# STM32N645 register map
File version: 1.0
CPU: CM55 r0p1, little endian, no MPU, FPU, vendor SysTick, 8 interrupt priority bits
Registers are 32-bit, read-write, reset 0x0 unless marked. A register's access mark holds for its fields unless they carry their own. Offsets are from the block's base; [hi:lo] are bit positions; lines under a group give offsets from that group; {n}, {i} and the like mark numbered series.

## ADC1 — Analog-to-digital converters
Base 0x40022000
Same registers: ADC2 0x40022100, ADC1_S 0x50022000, ADC2_S 0x50022100
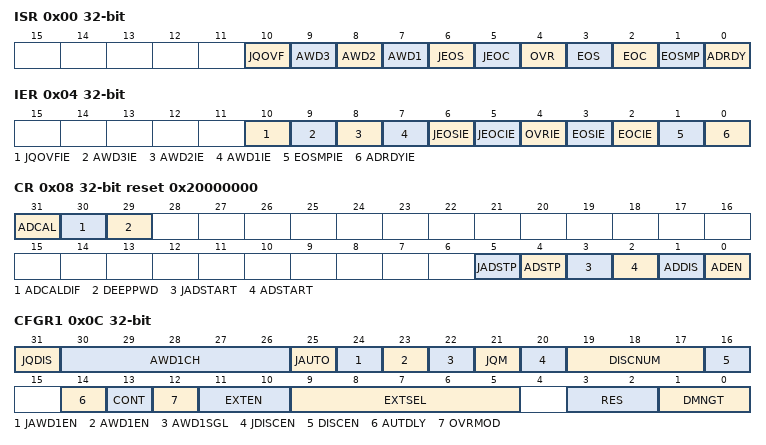
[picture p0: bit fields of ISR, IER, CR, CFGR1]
0x00 ISR — ADC interrupt and status register
  [10] JQOVF — Injected context queue overflow
  [9] AWD3 — Analog watchdog 3 flag
  [8] AWD2 — Analog watchdog 2 flag
  [7] AWD1 — Analog watchdog 1 flag
  [6] JEOS — Injected channel end of sequence flag
  [5] JEOC — Injected channel end of conversion flag
  [4] OVR — ADC overrun
  [3] EOS — End of regular sequence flag
  [2] EOC — End of conversion flag
  [1] EOSMP — End of sampling flag
  [0] ADRDY — ADC ready
0x04 IER — ADC interrupt enable register
  [10] JQOVFIE — Injected context queue overflow interrupt enable
  [9] AWD3IE — Analog watchdog 3 interrupt enable
  [8] AWD2IE — Analog watchdog 2 interrupt enable
  [7] AWD1IE — Analog watchdog 1 interrupt enable
  [6] JEOSIE — End of injected sequence of conversions interrupt enable
  [5] JEOCIE — End of injected conversion interrupt enable
  [4] OVRIE — Overrun interrupt enable
  [3] EOSIE — End of regular sequence of conversions interrupt enable
  [2] EOCIE — End of regular conversion interrupt enable
  [1] EOSMPIE — End of sampling flag interrupt enable for regular conversions
  [0] ADRDYIE — ADC ready interrupt enable
0x08 CR reset 0x20000000 — ADC control register
  [31] ADCAL — ADC calibration
  [30] ADCALDIF — Differential mode for calibration
  [29] DEEPPWD — Deep-power-down enable
  [5] JADSTP — ADC stop of injected conversion command
  [4] ADSTP — ADC stop of regular conversion command
  [3] JADSTART — ADC start of injected conversion
  [2] ADSTART — ADC start of regular conversion
  [1] ADDIS — ADC disable command
  [0] ADEN — ADC enable control
0x0C CFGR1 — ADC configuration register
  [31] JQDIS — Injected queue disable
  [30:26] AWD1CH — Analog watchdog 1 channel selection
  [25] JAUTO — Automatic injected group conversion
  [24] JAWD1EN — Analog watchdog 1 enable on injected channels
  [23] AWD1EN — Analog watchdog 1 enable on regular channels
  [22] AWD1SGL — Enable the watchdog 1 on a single channel or on all channels
  [21] JQM — JSQR queue mode
  [20] JDISCEN — Discontinuous mode on injected channels
  [19:17] DISCNUM — Discontinuous mode channel count
  [16] DISCEN — Discontinuous mode for regular channels
  [14] AUTDLY — Delayed conversion mode
  [13] CONT — Single / Continuous conversion mode for regular conversions
  [12] OVRMOD — Overrun mode
  [11:10] EXTEN — External trigger enable and polarity selection for regular channels
  [9:5] EXTSEL — External trigger selection for regular group
  [3:2] RES — Data resolution
  [1:0] DMNGT — Data management configuration
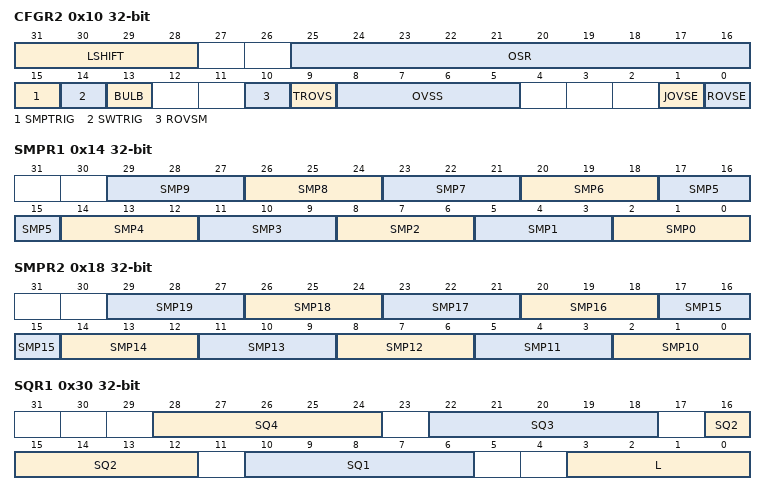
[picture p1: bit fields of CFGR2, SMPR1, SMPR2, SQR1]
0x10 CFGR2 — ADC configuration register 2
  [31:28] LSHIFT — Left shift factor
  [25:16] OSR — Oversampling ratio
  [15] SMPTRIG — Sampling time control trigger mode
  [14] SWTRIG — Software trigger bit for sampling time control trigger mode
  [13] BULB — Bulb sampling mode
  [10] ROVSM — Regular oversampling mode
  [9] TROVS — Triggered regular oversampling
  [8:5] OVSS — Oversampling shift
  [1] JOVSE — Injected oversampling enable
  [0] ROVSE — Regular oversampling enable
0x14 SMPR1 — ADC sample time register 1
  [3n+2:3n] SMP{n} (n=0..9) — Channel x sampling time selection
0x18 SMPR2 — ADC sample time register 2
  [3n-28:3n-30] SMP{n} (n=10..19) — Channel x sampling time selection
0x1C PCSEL — ADC channel preselection register
  [19:0] PCSEL — Channel i (V less than sub>INP less than /sub>[i]) preselection
0x30 SQR1 — ADC regular sequence register 1
  [28:24] SQ4 — 4th conversion in regular sequence
  [22:18] SQ3 — 3rd conversion in regular sequence
  [16:12] SQ2 — 2nd conversion in regular sequence
  [10:6] SQ1 — 1st conversion in regular sequence
  [3:0] L — Regular channel sequence length
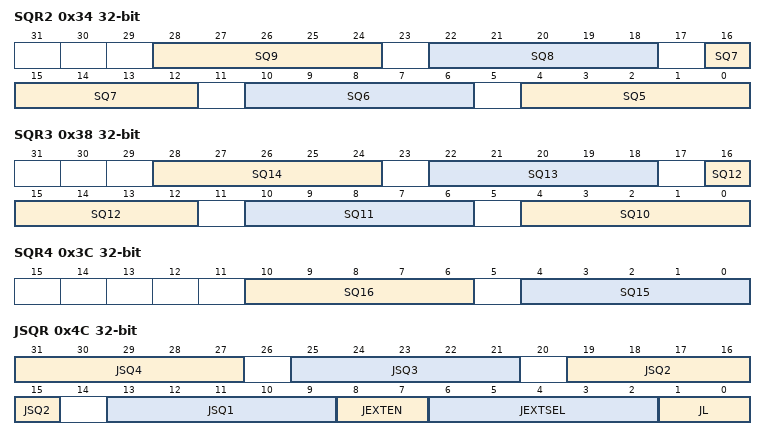
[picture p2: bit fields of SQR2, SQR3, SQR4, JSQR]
0x34 SQR2 — ADC regular sequence register 2
  [6n-26:6n-30] SQ{n} (n=5..9) — {n}th conversion in regular sequence
0x38 SQR3 — ADC regular sequence register 3
  [6n-56:6n-60] SQ{n} (n=10..14) — {n}th conversion in regular sequence
0x3C SQR4 — ADC regular sequence register 4
  [10:6] SQ16 — 16th conversion in regular sequence
  [4:0] SQ15 — 15th conversion in regular sequence
0x40 DR ro — ADC regular data register
  [31:0] RDATA — Regular data converted
0x4C JSQR — ADC injected sequence register
  [31:27] JSQ4 — 4th conversion in the injected sequence
  [25:21] JSQ3 — 3rd conversion in the injected sequence
  [19:15] JSQ2 — 2nd conversion in the injected sequence
  [13:9] JSQ1 — 1st conversion in the injected sequence
  [8:7] JEXTEN — External trigger enable and polarity selection for injected channels
  [6:2] JEXTSEL — External trigger selection for injected group
  [1:0] JL — Injected channel sequence length
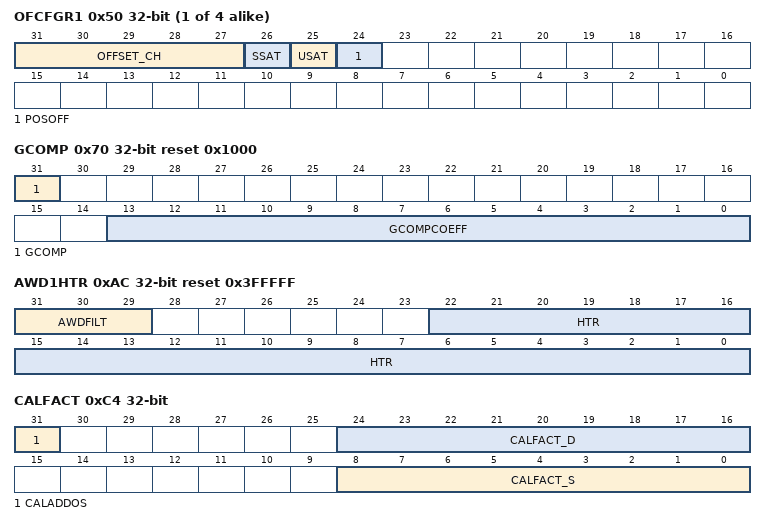
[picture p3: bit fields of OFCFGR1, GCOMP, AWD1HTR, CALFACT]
{0x4C+4i} OFCFGR{i} (i=1..4) — ADC offset {i} configuration register
  [31:27] OFFSET_CH — Channel selection for the data offset y
  [26] SSAT — Signed saturation enable
  [25] USAT — Unsigned saturation enable
  [24] POSOFF — Positive offset enable
{0x5C+4i} OFR{i} (i=1..4) — ADC offset {i} register
  [21:0] OFFSET — Data offset y for the channel programmed into OFFSETy_CH[4:0] bits
0x70 GCOMP reset 0x1000 — ADC gain compensation register
  [31] GCOMP — Gain compensation mode
  [13:0] GCOMPCOEFF — Gain compensation coefficient
{0x7C+4i} JDR{i} ro (i=1..4) — ADC injected channel {i} data register
  [31:0] JDATA — Injected data
0xA0 AWD2CR — ADC Analog Watchdog 2 Configuration Register
  [19:0] AWD2CH — Analog watchdog 2 channel selection
0xA4 AWD3CR — ADC Analog Watchdog 3 Configuration Register
  [19:0] AWD3CH — Analog watchdog 3 channel selection
{0xA0+8i} AWD{i}LTR (i=1..3) — ADC analog watchdog {i} lower threshold register
  [22:0] LTR — Analog watchdog {i} lower threshold
0xAC AWD1HTR reset 0x3FFFFF — ADC analog watchdog 1 higher threshold register
  [31:29] AWDFILT — Analog watchdog filtering parameter
  [22:0] HTR — Analog watchdog 1 higher threshold
0xB4 AWD2HTR reset 0x3FFFFF — ADC analog watchdog 2 higher threshold register
  [22:0] HTR — Analog watchdog 2 higher threshold
0xBC AWD3HTR reset 0x3FFFFF — ADC analog watchdog 3 higher threshold register
  [22:0] HTR — Analog watchdog 3 higher threshold
0xC0 DIFSEL — ADC Differential mode selection register
  [19:0] DIFSEL — Differential mode for channels 19 to 0.
0xC4 CALFACT — ADC calibration factors
  [31] CALADDOS — Calibration additional offset
  [24:16] CALFACT_D — Calibration factors in Differential mode
  [8:0] CALFACT_S — Calibration factors In Single-ended mode
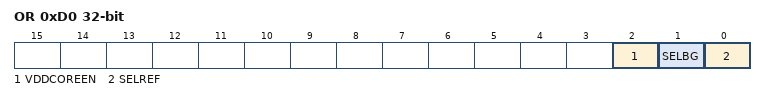
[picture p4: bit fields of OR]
0xD0 OR — ADC option register
  [2] VDDCOREEN — VDDCORE enable
  [1] SELBG — Bandgap selection
  [0] SELREF — Internal reference voltage selection
